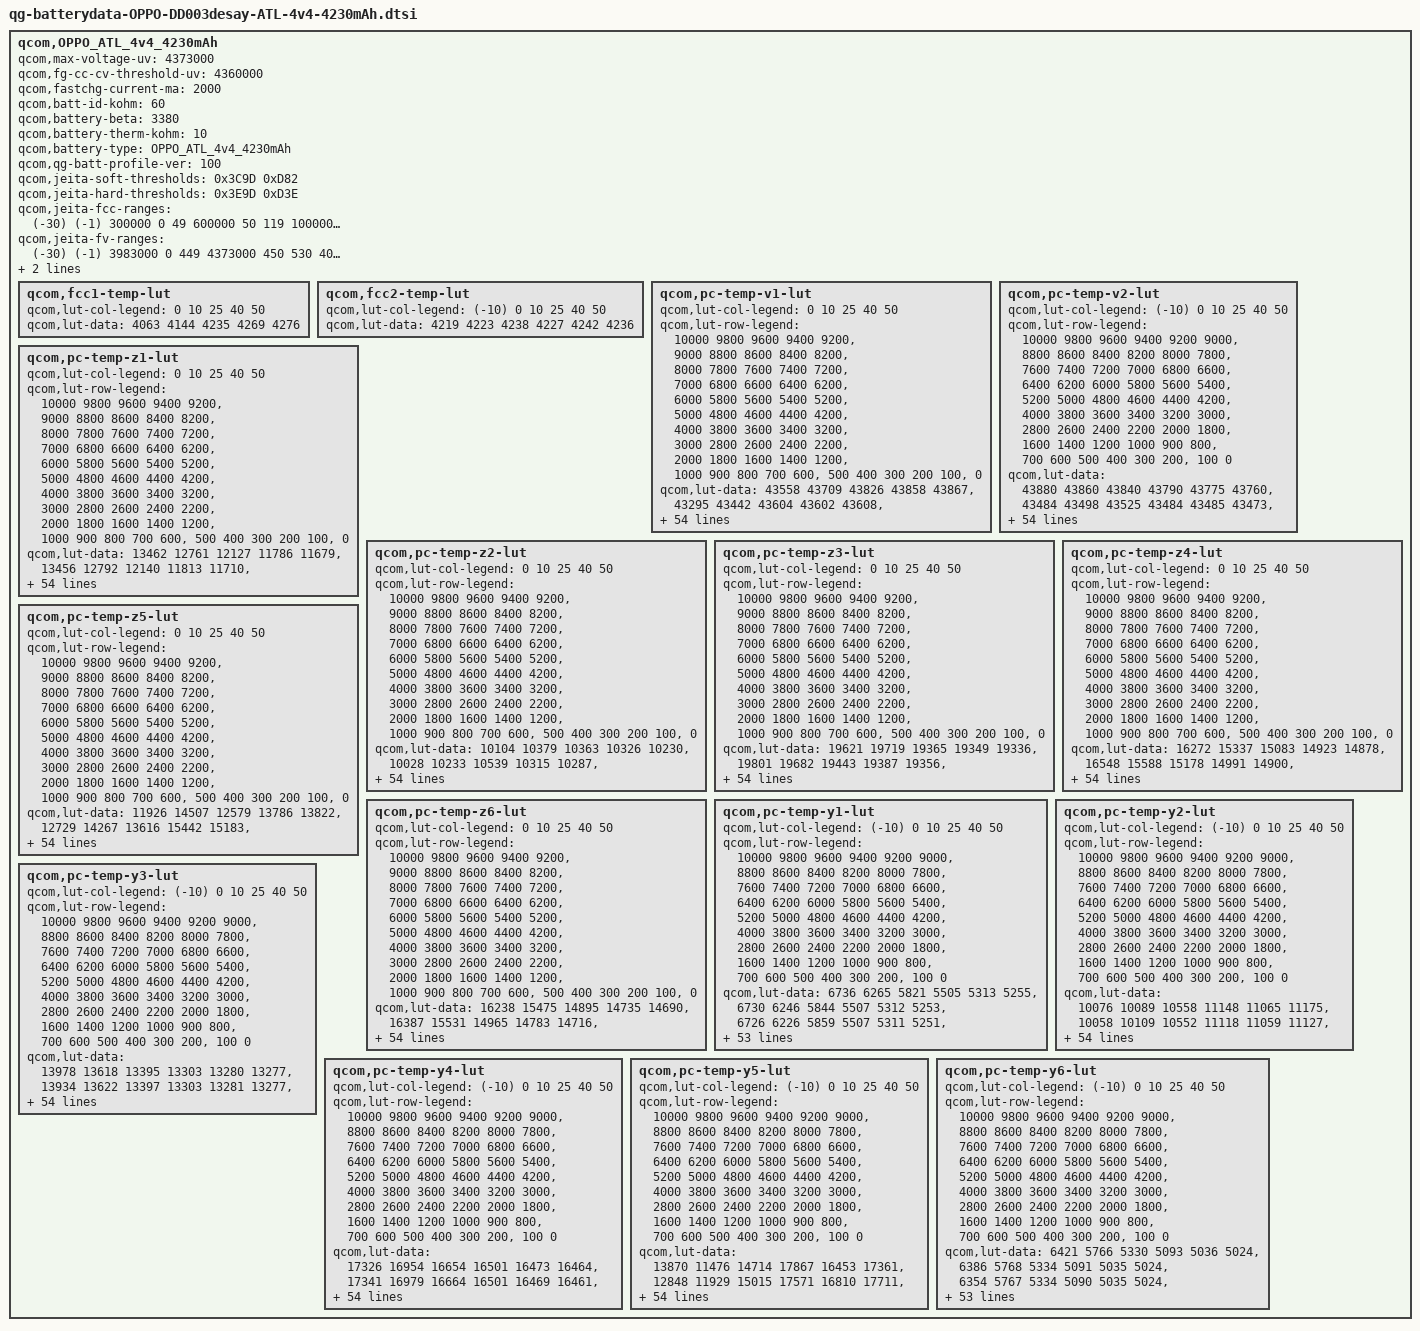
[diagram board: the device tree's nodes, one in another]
/*******************************************************************************
 *  Copyright (C), 2008-2018, OPPO Mobile Comm Corp., Ltd.
 *  ODM_WT_EDIT
 *  FILE: - qg-batterydata-OPPO-DD003desay-ATL-4v4-4230mAh.dtsi
 *  Description : The battery profile of ATL coil
 *  Version: 1.0
 *  Date : 2018/5/16
 *  Author: Bin2.Zhang@ODM_WT.BSP.Charger.Basic
 *
 *  -------------------------Revision History:----------------------------------
 *   <author>	 <data> 	<version >			<desc>
 *  Bin2.Zhang	2018/5/16	1.0				Add battery profile
 ******************************************************************************/
/* Copyright (c) 2018, The Linux Foundation. All rights reserved.
 *
 * This program is free software; you can redistribute it and/or modify
 * it under the terms of the GNU General Public License version 2 and
 * only version 2 as published by the Free Software Foundation.
 *
 * This program is distributed in the hope that it will be useful,
 * but WITHOUT ANY WARRANTY; without even the implied warranty of
 * MERCHANTABILITY or FITNESS FOR A PARTICULAR PURPOSE.  See the
 * GNU General Public License for more details.
 */

qcom,OPPO_ATL_4v4_4230mAh {
    /* 3444982_OPPO_DD003desay_4230mAh_averaged_MasterSlave_May8th2018 */
    qcom,max-voltage-uv = <4373000>;
    qcom,fg-cc-cv-threshold-uv = <4360000>;
    qcom,fastchg-current-ma = <2000>;
    qcom,batt-id-kohm = <60>; // (68|300) + 5.1
    qcom,battery-beta = <3380>;
    qcom,battery-therm-kohm = <10>;
    qcom,battery-type = "OPPO_ATL_4v4_4230mAh";
    qcom,qg-batt-profile-ver = <100>;

    ////From the attached of 80-p3255-39_a
	qcom,jeita-soft-thresholds = <0x3C9D 0xD82>; //disable in kernel
	qcom,jeita-hard-thresholds = <0x3E9D 0xD3E>; //<(-8) 58>;Use SW disable,also Enable in kernel
	qcom,jeita-fcc-ranges = < (-30) (-1) 300000
				0    49  600000
				50   119  1000000
				120  219  1800000
				220  449  2000000
				450  530  1000000>;
	qcom,jeita-fv-ranges = < (-30) (-1) 3983000
				0   449  4373000
				450 530  4083000>;
	qcom,jeita-rechr-uv-ranges = < (-30) (-1) 3700000
				0   49   4150000
				50  449  4270000
				450 530  3980000>;

	qcom,fcc1-temp-lut {
		qcom,lut-col-legend = <0 10 25 40 50>;
		qcom,lut-data = <4063 4144 4235 4269 4276>;
	};

	qcom,fcc2-temp-lut {
		qcom,lut-col-legend = <(-10) 0 10 25 40 50>;
		qcom,lut-data = <4219 4223 4238 4227 4242 4236>;
		//qcom,lut-col-legend = <(-20) (-10) 0 10 25 40 50>;
		//qcom,lut-data = <4218 4219 4223 4238 4227 4242 4236>;
	};

	qcom,pc-temp-v1-lut {
		qcom,lut-col-legend = <0 10 25 40 50>;
		qcom,lut-row-legend = <10000 9800 9600 9400 9200>,
			<9000 8800 8600 8400 8200>,
			<8000 7800 7600 7400 7200>,
			<7000 6800 6600 6400 6200>,
			<6000 5800 5600 5400 5200>,
			<5000 4800 4600 4400 4200>,
			<4000 3800 3600 3400 3200>,
			<3000 2800 2600 2400 2200>,
			<2000 1800 1600 1400 1200>,
			<1000 900 800 700 600>,
			<500 400 300 200 100>,
			<0>;
		qcom,lut-data = <43558 43709 43826 43858 43867>,
			<43295 43442 43604 43602 43608>,
			<43044 43189 43351 43362 43368>,
			<42801 42949 43104 43127 43133>,
			<42566 42715 42858 42891 42902>,
			<42337 42480 42616 42656 42674>,
			<42113 42248 42383 42423 42444>,
			<41894 42022 42155 42192 42213>,
			<41681 41801 41928 41965 41985>,
			<41477 41586 41700 41739 41757>,
			<41282 41378 41478 41516 41531>,
			<41085 41177 41271 41297 41313>,
			<40878 40976 41071 41081 41098>,
			<40666 40780 40868 40873 40890>,
			<40449 40581 40656 40671 40685>,
			<40218 40372 40450 40475 40488>,
			<40009 40156 40251 40284 40299>,
			<39849 39971 40062 40101 40120>,
			<39714 39828 39896 39928 39947>,
			<39584 39699 39760 39778 39791>,
			<39456 39558 39612 39622 39630>,
			<39332 39412 39413 39410 39426>,
			<39209 39249 39185 39146 39178>,
			<39090 39025 38982 38943 38976>,
			<38967 38791 38784 38803 38830>,
			<38831 38644 38635 38689 38708>,
			<38694 38542 38551 38588 38600>,
			<38580 38466 38489 38498 38504>,
			<38479 38413 38424 38413 38414>,
			<38397 38371 38357 38330 38325>,
			<38341 38329 38294 38253 38243>,
			<38296 38287 38234 38185 38171>,
			<38259 38246 38178 38124 38107>,
			<38227 38208 38128 38068 38047>,
			<38198 38172 38086 38018 37993>,
			<38168 38136 38045 37970 37939>,
			<38138 38105 38006 37922 37880>,
			<38102 38067 37965 37874 37819>,
			<38048 38007 37906 37810 37746>,
			<37977 37917 37818 37723 37658>,
			<37889 37817 37716 37621 37558>,
			<37768 37703 37607 37512 37449>,
			<37630 37572 37482 37386 37323>,
			<37473 37412 37322 37229 37166>,
			<37328 37267 37175 37087 37027>,
			<37245 37168 37076 36993 36936>,
			<37216 37143 37052 36965 36913>,
			<37187 37120 37032 36951 36894>,
			<37161 37097 37012 36931 36874>,
			<37114 37059 36968 36876 36814>,
			<36905 36836 36740 36617 36546>,
			<36460 36400 36308 36178 36113>,
			<35885 35827 35737 35602 35544>,
			<35103 35044 34957 34816 34769>,
			<33866 33815 33746 33588 33573>,
			<30000 30000 30000 30000 30000>;
	};

	qcom,pc-temp-v2-lut {
		qcom,lut-col-legend = <(-10) 0 10 25 40 50>;
		qcom,lut-row-legend = <10000 9800 9600 9400 9200 9000>,
			<8800 8600 8400 8200 8000 7800>,
			<7600 7400 7200 7000 6800 6600>,
			<6400 6200 6000 5800 5600 5400>,
			<5200 5000 4800 4600 4400 4200>,
			<4000 3800 3600 3400 3200 3000>,
			<2800 2600 2400 2200 2000 1800>,
			<1600 1400 1200 1000 900 800>,
			<700 600 500 400 300 200>,
			<100 0>;
		qcom,lut-data = <43880 43860 43840 43790 43775 43760>,
			<43484 43498 43525 43484 43485 43473>,
			<43129 43170 43232 43199 43213 43204>,
			<42819 42880 42963 42938 42958 42951>,
			<42544 42626 42718 42700 42721 42716>,
			<42302 42382 42480 42467 42489 42486>,
			<42100 42141 42241 42233 42257 42253>,
			<41915 41905 42007 42003 42026 42023>,
			<41685 41674 41779 41777 41798 41797>,
			<41394 41443 41558 41556 41573 41572>,
			<41158 41232 41343 41339 41352 41351>,
			<41040 41061 41137 41125 41136 41135>,
			<40943 40901 40936 40914 40924 40921>,
			<40734 40700 40736 40709 40720 40717>,
			<40270 40452 40535 40507 40520 40517>,
			<39852 40191 40331 40311 40327 40325>,
			<39624 39920 40119 40114 40137 40140>,
			<39446 39652 39904 39925 39953 39962>,
			<39273 39441 39688 39757 39783 39793>,
			<39112 39273 39469 39614 39629 39637>,
			<38956 39116 39264 39454 39458 39465>,
			<38795 38961 39073 39224 39234 39243>,
			<38640 38812 38897 38971 38999 39010>,
			<38509 38656 38742 38785 38817 38827>,
			<38395 38488 38602 38640 38664 38675>,
			<38297 38344 38479 38516 38534 38545>,
			<38216 38236 38373 38406 38423 38432>,
			<38146 38146 38276 38307 38325 38333>,
			<38081 38077 38176 38217 38235 38242>,
			<38019 38021 38074 38133 38153 38158>,
			<37961 37971 37991 38058 38079 38082>,
			<37904 37923 37928 37989 38011 38013>,
			<37850 37877 37877 37925 37948 37949>,
			<37792 37831 37831 37865 37882 37881>,
			<37733 37787 37792 37811 37814 37812>,
			<37673 37741 37753 37755 37740 37733>,
			<37612 37693 37715 37695 37651 37626>,
			<37549 37640 37675 37633 37559 37510>,
			<37482 37580 37621 37564 37476 37416>,
			<37409 37514 37550 37492 37398 37337>,
			<37338 37437 37467 37411 37315 37255>,
			<37270 37343 37367 37314 37224 37163>,
			<37205 37233 37249 37201 37119 37059>,
			<37141 37109 37106 37068 36983 36928>,
			<37070 36993 36972 36940 36866 36816>,
			<36978 36898 36877 36871 36819 36769>,
			<36922 36856 36846 36859 36805 36755>,
			<36865 36818 36813 36839 36790 36741>,
			<36790 36775 36770 36810 36761 36711>,
			<36675 36700 36679 36739 36665 36616>,
			<36449 36512 36471 36482 36353 36300>,
			<36054 36095 36032 36006 35845 35811>,
			<35458 35479 35408 35391 35193 35171>,
			<34592 34622 34540 34532 34292 34298>,
			<33160 33237 33217 33208 32875 32956>,
			<28418 27954 28007 28289 27814 28701>;
	};

	qcom,pc-temp-z1-lut {
		qcom,lut-col-legend = <0 10 25 40 50>;
		qcom,lut-row-legend = <10000 9800 9600 9400 9200>,
			<9000 8800 8600 8400 8200>,
			<8000 7800 7600 7400 7200>,
			<7000 6800 6600 6400 6200>,
			<6000 5800 5600 5400 5200>,
			<5000 4800 4600 4400 4200>,
			<4000 3800 3600 3400 3200>,
			<3000 2800 2600 2400 2200>,
			<2000 1800 1600 1400 1200>,
			<1000 900 800 700 600>,
			<500 400 300 200 100>,
			<0>;
		qcom,lut-data = <13462 12761 12127 11786 11679>,
			<13456 12792 12140 11813 11710>,
			<13463 12797 12137 11814 11711>,
			<13469 12779 12133 11813 11712>,
			<13462 12764 12124 11809 11712>,
			<13444 12757 12115 11803 11712>,
			<13434 12743 12105 11800 11712>,
			<13433 12735 12096 11797 11713>,
			<13435 12717 12089 11796 11713>,
			<13437 12698 12082 11796 11714>,
			<13440 12690 12079 11796 11715>,
			<13440 12684 12079 11796 11715>,
			<13411 12676 12080 11796 11716>,
			<13366 12664 12080 11796 11716>,
			<13350 12651 12076 11794 11716>,
			<13346 12642 12074 11792 11715>,
			<13342 12630 12075 11792 11716>,
			<13327 12626 12077 11793 11716>,
			<13296 12630 12078 11794 11717>,
			<13284 12637 12080 11796 11719>,
			<13289 12641 12082 11798 11720>,
			<13294 12647 12086 11799 11721>,
			<13298 12651 12092 11801 11722>,
			<13300 12655 12096 11802 11723>,
			<13303 12659 12099 11805 11725>,
			<13311 12663 12102 11808 11727>,
			<13320 12673 12105 11811 11730>,
			<13323 12678 12109 11815 11733>,
			<13316 12677 12113 11819 11737>,
			<13311 12676 12117 11823 11741>,
			<13319 12677 12122 11828 11745>,
			<13332 12678 12128 11832 11749>,
			<13337 12681 12136 11837 11753>,
			<13339 12688 12144 11842 11756>,
			<13343 12700 12151 11845 11760>,
			<13349 12707 12157 11849 11763>,
			<13361 12719 12161 11853 11766>,
			<13371 12729 12165 11859 11768>,
			<13382 12733 12168 11863 11771>,
			<13394 12743 12175 11867 11774>,
			<13397 12751 12182 11871 11776>,
			<13396 12759 12192 11876 11780>,
			<13396 12766 12201 11880 11783>,
			<13397 12761 12201 11883 11786>,
			<13397 12775 12211 11888 11790>,
			<13412 12780 12215 11892 11791>,
			<13409 12773 12225 11893 11792>,
			<13426 12780 12215 11893 11793>,
			<13414 12753 12214 11895 11794>,
			<13397 12760 12224 11899 11798>,
			<13409 12802 12223 11906 11803>,
			<13452 12800 12245 11913 11809>,
			<13482 12806 12255 11921 11818>,
			<13458 12841 12268 11936 11830>,
			<13458 12841 12268 11936 11830>,
			<13458 12841 12268 11936 11830>;
	};

	qcom,pc-temp-z2-lut {
		qcom,lut-col-legend = <0 10 25 40 50>;
		qcom,lut-row-legend = <10000 9800 9600 9400 9200>,
			<9000 8800 8600 8400 8200>,
			<8000 7800 7600 7400 7200>,
			<7000 6800 6600 6400 6200>,
			<6000 5800 5600 5400 5200>,
			<5000 4800 4600 4400 4200>,
			<4000 3800 3600 3400 3200>,
			<3000 2800 2600 2400 2200>,
			<2000 1800 1600 1400 1200>,
			<1000 900 800 700 600>,
			<500 400 300 200 100>,
			<0>;
		qcom,lut-data = <10104 10379 10363 10326 10230>,
			<10028 10233 10539 10315 10287>,
			<10048 10183 10931 10462 10468>,
			<10071 10170 10999 10558 10596>,
			<10089 10159 10639 10543 10572>,
			<10108 10137 10344 10513 10522>,
			<10118 10111 10404 10483 10488>,
			<10124 10096 10542 10442 10453>,
			<10127 10086 10554 10417 10433>,
			<10126 10080 10386 10609 10439>,
			<10115 10079 10255 10899 10451>,
			<10101 10079 10300 10944 10426>,
			<10075 10081 10409 10923 10307>,
			<10040 10099 10502 10910 10239>,
			<10012 10125 10596 10929 10272>,
			<9983 10144 10652 10956 10316>,
			<9966 10159 10572 10872 10325>,
			<9971 10180 10415 10525 10326>,
			<9990 10223 10382 10346 10329>,
			<10008 10263 10399 10332 10345>,
			<10026 10272 10423 10328 10376>,
			<10042 10274 10463 10429 10472>,
			<10054 10276 10509 10668 10690>,
			<10061 10277 10513 10752 10778>,
			<10070 10278 10470 10543 10604>,
			<10082 10280 10435 10328 10413>,
			<10097 10283 10432 10330 10419>,
			<10110 10287 10434 10381 10487>,
			<10124 10291 10445 10444 10529>,
			<10138 10296 10484 10546 10550>,
			<10149 10301 10510 10622 10560>,
			<10159 10308 10503 10588 10488>,
			<10171 10317 10488 10500 10321>,
			<10185 10326 10479 10473 10265>,
			<10200 10335 10470 10504 10300>,
			<10216 10342 10465 10544 10351>,
			<10235 10346 10480 10571 10402>,
			<10252 10350 10511 10596 10458>,
			<10265 10359 10537 10628 10502>,
			<10279 10374 10562 10677 10541>,
			<10295 10385 10582 10707 10565>,
			<10317 10391 10594 10689 10561>,
			<10345 10400 10604 10654 10549>,
			<10385 10429 10614 10633 10534>,
			<10701 10620 10686 10624 10528>,
			<10558 10709 10738 10602 10536>,
			<10463 10733 10730 10580 10539>,
			<10427 10752 10708 10607 10529>,
			<10418 10781 10712 10615 10564>,
			<10397 10900 10752 10762 10695>,
			<10386 10850 10933 10747 10482>,
			<10305 10804 10847 10570 10343>,
			<10079 10697 10816 10494 10283>,
			<9915 10548 10747 10438 10230>,
			<9915 10548 10747 10438 10230>,
			<9915 10548 10747 10438 10230>;
	};

	qcom,pc-temp-z3-lut {
		qcom,lut-col-legend = <0 10 25 40 50>;
		qcom,lut-row-legend = <10000 9800 9600 9400 9200>,
			<9000 8800 8600 8400 8200>,
			<8000 7800 7600 7400 7200>,
			<7000 6800 6600 6400 6200>,
			<6000 5800 5600 5400 5200>,
			<5000 4800 4600 4400 4200>,
			<4000 3800 3600 3400 3200>,
			<3000 2800 2600 2400 2200>,
			<2000 1800 1600 1400 1200>,
			<1000 900 800 700 600>,
			<500 400 300 200 100>,
			<0>;
		qcom,lut-data = <19621 19719 19365 19349 19336>,
			<19801 19682 19443 19387 19356>,
			<19885 19684 19478 19410 19383>,
			<19923 19702 19498 19424 19399>,
			<19917 19713 19514 19433 19402>,
			<19896 19715 19526 19438 19404>,
			<19874 19715 19534 19438 19405>,
			<19845 19714 19540 19434 19404>,
			<19822 19705 19537 19431 19403>,
			<19819 19693 19519 19432 19400>,
			<19820 19686 19504 19436 19395>,
			<19821 19679 19507 19435 19388>,
			<19829 19669 19518 19428 19376>,
			<19841 19644 19518 19422 19369>,
			<19852 19620 19507 19416 19366>,
			<19874 19613 19492 19410 19364>,
			<19891 19610 19475 19402 19361>,
			<19879 19605 19458 19384 19355>,
			<19846 19583 19450 19372 19350>,
			<19822 19559 19442 19366 19346>,
			<19807 19560 19438 19362 19343>,
			<19797 19579 19450 19369 19347>,
			<19796 19600 19471 19389 19361>,
			<19797 19620 19475 19397 19366>,
			<19799 19637 19469 19377 19348>,
			<19811 19639 19459 19356 19327>,
			<19828 19636 19448 19353 19326>,
			<19831 19630 19437 19352 19332>,
			<19827 19621 19435 19354 19341>,
			<19819 19610 19441 19377 19365>,
			<19809 19602 19448 19400 19386>,
			<19795 19597 19459 19402 19385>,
			<19780 19594 19470 19403 19379>,
			<19764 19593 19472 19403 19372>,
			<19747 19593 19466 19396 19364>,
			<19732 19592 19460 19388 19358>,
			<19716 19586 19454 19383 19356>,
			<19705 19580 19449 19378 19355>,
			<19700 19578 19446 19374 19354>,
			<19696 19577 19443 19371 19351>,
			<19689 19575 19440 19368 19349>,
			<19677 19569 19435 19367 19350>,
			<19663 19559 19429 19365 19351>,
			<19645 19544 19425 19363 19352>,
			<19555 19495 19411 19355 19348>,
			<19403 19475 19402 19350 19342>,
			<19338 19452 19393 19350 19330>,
			<19336 19442 19388 19338 19329>,
			<19327 19434 19388 19336 19325>,
			<19316 19386 19384 19327 19320>,
			<19328 19429 19357 19326 19345>,
			<19334 19382 19354 19342 19348>,
			<19341 19345 19349 19344 19349>,
			<19344 19344 19343 19345 19350>,
			<19344 19344 19343 19345 19350>,
			<19344 19344 19343 19345 19350>;
	};

	qcom,pc-temp-z4-lut {
		qcom,lut-col-legend = <0 10 25 40 50>;
		qcom,lut-row-legend = <10000 9800 9600 9400 9200>,
			<9000 8800 8600 8400 8200>,
			<8000 7800 7600 7400 7200>,
			<7000 6800 6600 6400 6200>,
			<6000 5800 5600 5400 5200>,
			<5000 4800 4600 4400 4200>,
			<4000 3800 3600 3400 3200>,
			<3000 2800 2600 2400 2200>,
			<2000 1800 1600 1400 1200>,
			<1000 900 800 700 600>,
			<500 400 300 200 100>,
			<0>;
		qcom,lut-data = <16272 15337 15083 14923 14878>,
			<16548 15588 15178 14991 14900>,
			<16306 15590 15119 14959 14888>,
			<16021 15421 15064 14921 14870>,
			<15844 15249 15005 14887 14848>,
			<15696 15149 14947 14854 14823>,
			<15579 15070 14888 14829 14802>,
			<15492 15009 14831 14809 14783>,
			<15417 14961 14806 14788 14766>,
			<15342 14921 14795 14757 14750>,
			<15271 14889 14787 14724 14737>,
			<15205 14861 14755 14711 14733>,
			<15144 14840 14705 14704 14731>,
			<15088 14825 14689 14698 14729>,
			<15040 14813 14693 14690 14720>,
			<14995 14807 14700 14682 14709>,
			<14958 14802 14707 14681 14701>,
			<14933 14798 14714 14690 14694>,
			<14914 14794 14711 14694 14689>,
			<14894 14789 14698 14689 14683>,
			<14870 14777 14690 14684 14679>,
			<14847 14750 14704 14700 14692>,
			<14830 14736 14738 14756 14744>,
			<14816 14778 14777 14801 14789>,
			<14807 14842 14835 14832 14822>,
			<14806 14858 14870 14852 14844>,
			<14807 14861 14864 14849 14839>,
			<14811 14862 14850 14835 14818>,
			<14822 14854 14834 14814 14791>,
			<14831 14835 14811 14775 14748>,
			<14829 14819 14786 14735 14710>,
			<14822 14804 14758 14715 14698>,
			<14815 14790 14732 14700 14690>,
			<14809 14775 14720 14694 14687>,
			<14804 14759 14713 14691 14685>,
			<14799 14749 14710 14690 14685>,
			<14795 14742 14709 14692 14686>,
			<14790 14738 14709 14696 14692>,
			<14780 14739 14711 14702 14698>,
			<14770 14742 14724 14715 14709>,
			<14768 14743 14734 14723 14715>,
			<14772 14741 14729 14718 14709>,
			<14772 14739 14723 14711 14700>,
			<14762 14738 14722 14714 14701>,
			<14750 14722 14710 14709 14695>,
			<14878 14707 14690 14690 14680>,
			<14945 14721 14687 14681 14680>,
			<14943 14724 14677 14674 14665>,
			<14944 14723 14663 14657 14646>,
			<14945 14770 14666 14664 14648>,
			<14934 14732 14717 14699 14658>,
			<14953 14802 14731 14689 14662>,
			<14960 14848 14739 14691 14663>,
			<14974 14858 14751 14691 14664>,
			<14974 14858 14751 14691 14664>,
			<14974 14858 14751 14691 14664>;
	};

	qcom,pc-temp-z5-lut {
		qcom,lut-col-legend = <0 10 25 40 50>;
		qcom,lut-row-legend = <10000 9800 9600 9400 9200>,
			<9000 8800 8600 8400 8200>,
			<8000 7800 7600 7400 7200>,
			<7000 6800 6600 6400 6200>,
			<6000 5800 5600 5400 5200>,
			<5000 4800 4600 4400 4200>,
			<4000 3800 3600 3400 3200>,
			<3000 2800 2600 2400 2200>,
			<2000 1800 1600 1400 1200>,
			<1000 900 800 700 600>,
			<500 400 300 200 100>,
			<0>;
		qcom,lut-data = <11926 14507 12579 13786 13822>,
			<12729 14267 13616 15442 15183>,
			<13292 14495 14694 16564 17074>,
			<13624 14948 15517 17369 18186>,
			<13714 15429 16427 17992 18368>,
			<13766 15902 17380 18456 18467>,
			<13789 16368 18463 18650 18627>,
			<13757 16739 19552 18702 18854>,
			<13720 17007 19870 18696 19141>,
			<13776 17294 19584 20868 19653>,
			<13993 17821 19386 24109 20188>,
			<14234 18502 22212 24737 20067>,
			<14477 18732 27514 24904 19123>,
			<14803 18606 28961 24948 18590>,
			<15335 18469 28413 26043 19197>,
			<16711 18663 27470 27560 20075>,
			<17787 19285 25488 26803 20367>,
			<17745 19562 22910 22845 20496>,
			<17522 18870 22492 20972 20664>,
			<17450 18017 23238 21457 21151>,
			<18094 18845 24579 22370 22045>,
			<19260 23576 34044 27157 24875>,
			<20558 29731 49205 38487 31150>,
			<22306 39430 51496 42527 33563>,
			<24807 49227 42374 32165 26101>,
			<30979 50149 32823 20598 17532>,
			<38782 44788 26952 17939 16095>,
			<41605 38823 22436 16617 15603>,
			<41954 34173 21395 16411 15631>,
			<41440 30076 21272 18342 18444>,
			<39695 28263 21312 21260 21987>,
			<36548 27349 23854 24268 23694>,
			<33602 26923 28525 27670 24897>,
			<30869 27727 31000 29980 25978>,
			<28430 29556 32679 31738 27125>,
			<26665 30298 33483 32689 27878>,
			<25051 30265 33396 32098 28059>,
			<24308 30229 33139 30362 28161>,
			<24956 30889 32517 28358 27883>,
			<26027 32415 30436 25587 24904>,
			<26236 32987 28106 23208 22154>,
			<25707 30994 25997 22018 21595>,
			<25343 28577 24372 21139 21327>,
			<25648 26533 23623 20247 21222>,
			<23842 26146 23878 19683 20693>,
			<15775 25923 24828 19787 20146>,
			<12452 20500 22421 20304 17790>,
			<12394 19270 22093 18536 18491>,
			<12255 18856 23353 19782 20644>,
			<12122 16513 22675 17896 19170>,
			<12411 18443 16129 15004 19686>,
			<12318 14548 14985 15775 18696>,
			<12220 12895 14388 15568 18031>,
			<12068 12653 13788 15296 17340>,
			<12068 12653 13788 15296 17340>,
			<12068 12653 13788 15296 17340>;
	};

	qcom,pc-temp-z6-lut {
		qcom,lut-col-legend = <0 10 25 40 50>;
		qcom,lut-row-legend = <10000 9800 9600 9400 9200>,
			<9000 8800 8600 8400 8200>,
			<8000 7800 7600 7400 7200>,
			<7000 6800 6600 6400 6200>,
			<6000 5800 5600 5400 5200>,
			<5000 4800 4600 4400 4200>,
			<4000 3800 3600 3400 3200>,
			<3000 2800 2600 2400 2200>,
			<2000 1800 1600 1400 1200>,
			<1000 900 800 700 600>,
			<500 400 300 200 100>,
			<0>;
		qcom,lut-data = <16238 15475 14895 14735 14690>,
			<16387 15531 14965 14783 14716>,
			<16278 15527 14960 14782 14724>,
			<16141 15442 14950 14779 14726>,
			<16033 15348 14929 14770 14721>,
			<15930 15292 14904 14756 14710>,
			<15844 15245 14882 14744 14701>,
			<15773 15205 14859 14733 14694>,
			<15713 15170 14841 14723 14686>,
			<15665 15140 14827 14711 14678>,
			<15624 15117 14813 14700 14670>,
			<15587 15098 14798 14692 14663>,
			<15548 15076 14784 14686 14656>,
			<15512 15047 14775 14679 14650>,
			<15488 15022 14771 14672 14645>,
			<15471 15014 14767 14665 14639>,
			<15456 15009 14761 14659 14633>,
			<15432 15004 14754 14653 14627>,
			<15403 14990 14746 14647 14622>,
			<15380 14978 14738 14642 14617>,
			<15360 14976 14733 14638 14613>,
			<15346 14978 14745 14650 14622>,
			<15341 14981 14771 14688 14655>,
			<15338 15009 14793 14705 14672>,
			<15337 15048 14814 14707 14675>,
			<15343 15057 14825 14708 14677>,
			<15354 15058 14819 14706 14675>,
			<15360 15058 14808 14700 14670>,
			<15363 15052 14801 14694 14664>,
			<15365 15039 14795 14690 14660>,
			<15363 15030 14790 14685 14655>,
			<15354 15023 14785 14680 14650>,
			<15344 15017 14781 14675 14644>,
			<15335 15012 14777 14671 14639>,
			<15326 15008 14773 14666 14634>,
			<15319 15004 14770 14663 14631>,
			<15312 15001 14767 14662 14631>,
			<15309 14999 14765 14661 14632>,
			<15309 15001 14766 14661 14634>,
			<15309 15006 14772 14665 14637>,
			<15309 15009 14776 14668 14639>,
			<15311 15009 14773 14666 14637>,
			<15312 15008 14770 14663 14634>,
			<15308 15006 14769 14663 14635>,
			<15267 14986 14760 14658 14631>,
			<15251 14973 14749 14648 14623>,
			<15246 14967 14744 14644 14617>,
			<15245 14963 14737 14635 14609>,
			<15241 14960 14732 14626 14599>,
			<15241 14959 14733 14626 14597>,
			<15251 14972 14743 14642 14616>,
			<15269 14984 14751 14648 14622>,
			<15289 14994 14756 14652 14625>,
			<15319 15012 14763 14656 14630>,
			<15319 15012 14763 14656 14630>,
			<15319 15012 14763 14656 14630>;
	};

	qcom,pc-temp-y1-lut {
		qcom,lut-col-legend = <(-10) 0 10 25 40 50>;
		qcom,lut-row-legend = <10000 9800 9600 9400 9200 9000>,
			<8800 8600 8400 8200 8000 7800>,
			<7600 7400 7200 7000 6800 6600>,
			<6400 6200 6000 5800 5600 5400>,
			<5200 5000 4800 4600 4400 4200>,
			<4000 3800 3600 3400 3200 3000>,
			<2800 2600 2400 2200 2000 1800>,
			<1600 1400 1200 1000 900 800>,
			<700 600 500 400 300 200>,
			<100 0>;
		qcom,lut-data = <6736 6265 5821 5505 5313 5255>,
			<6730 6246 5844 5507 5312 5253>,
			<6726 6226 5859 5507 5311 5251>,
			<6722 6208 5867 5507 5310 5249>,
			<6720 6195 5871 5506 5309 5247>,
			<6720 6190 5872 5505 5307 5245>,
			<6721 6193 5866 5502 5305 5244>,
			<6723 6198 5854 5497 5303 5244>,
			<6722 6201 5848 5495 5301 5243>,
			<6718 6202 5841 5494 5300 5242>,
			<6713 6202 5837 5493 5298 5241>,
			<6716 6206 5838 5492 5297 5240>,
			<6722 6213 5841 5490 5296 5240>,
			<6723 6215 5841 5490 5295 5239>,
			<6717 6215 5839 5488 5294 5239>,
			<6713 6215 5839 5488 5294 5239>,
			<6714 6213 5846 5488 5295 5240>,
			<6716 6210 5855 5488 5296 5241>,
			<6716 6209 5855 5489 5296 5241>,
			<6713 6209 5846 5490 5296 5241>,
			<6710 6209 5842 5492 5296 5241>,
			<6712 6208 5846 5493 5297 5241>,
			<6715 6207 5854 5495 5298 5242>,
			<6712 6208 5856 5497 5299 5242>,
			<6698 6218 5855 5503 5301 5244>,
			<6684 6224 5854 5508 5303 5246>,
			<6674 6223 5851 5511 5305 5247>,
			<6666 6220 5848 5515 5307 5249>,
			<6662 6215 5849 5520 5310 5251>,
			<6658 6209 5851 5529 5313 5254>,
			<6656 6204 5854 5534 5317 5256>,
			<6657 6199 5856 5534 5320 5259>,
			<6659 6192 5858 5534 5324 5261>,
			<6660 6192 5859 5536 5328 5264>,
			<6665 6197 5863 5543 5332 5266>,
			<6669 6201 5866 5549 5335 5269>,
			<6659 6204 5873 5553 5337 5270>,
			<6643 6208 5882 5557 5338 5272>,
			<6634 6205 5884 5558 5340 5273>,
			<6631 6189 5883 5557 5341 5275>,
			<6628 6177 5882 5557 5343 5277>,
			<6628 6187 5871 5561 5344 5278>,
			<6631 6197 5863 5566 5346 5280>,
			<6643 6179 5873 5573 5349 5282>,
			<6657 6184 5891 5586 5354 5285>,
			<6692 6219 5878 5584 5359 5287>,
			<6691 6212 5884 5586 5359 5288>,
			<6667 6200 5875 5586 5360 5287>,
			<6702 6195 5878 5598 5359 5287>,
			<6703 6209 5884 5607 5359 5288>,
			<6693 6198 5899 5603 5362 5290>,
			<6688 6211 5917 5607 5369 5295>,
			<6680 6222 5917 5629 5377 5301>,
			<6735 6237 5918 5639 5388 5310>,
			<6735 6237 5918 5639 5388 5310>,
			<6735 6237 5918 5639 5388 5310>;
	};

	qcom,pc-temp-y2-lut {
		qcom,lut-col-legend = <(-10) 0 10 25 40 50>;
		qcom,lut-row-legend = <10000 9800 9600 9400 9200 9000>,
			<8800 8600 8400 8200 8000 7800>,
			<7600 7400 7200 7000 6800 6600>,
			<6400 6200 6000 5800 5600 5400>,
			<5200 5000 4800 4600 4400 4200>,
			<4000 3800 3600 3400 3200 3000>,
			<2800 2600 2400 2200 2000 1800>,
			<1600 1400 1200 1000 900 800>,
			<700 600 500 400 300 200>,
			<100 0>;
		qcom,lut-data = <10076 10089 10558 11148 11065 11175>,
			<10058 10109 10552 11118 11059 11127>,
			<10062 10134 10549 11080 11038 11080>,
			<10086 10159 10548 11042 11009 11035>,
			<10123 10180 10548 11009 10982 10995>,
			<10171 10193 10550 10990 10964 10962>,
			<10237 10197 10552 10983 10947 10934>,
			<10316 10201 10556 10978 10930 10910>,
			<10387 10235 10562 10969 10932 10894>,
			<10462 10379 10572 10951 10958 10881>,
			<10510 10476 10586 10941 10988 10876>,
			<10529 10475 10607 10947 11021 10895>,
			<10543 10471 10640 10962 11052 10931>,
			<10514 10486 10691 10983 11063 10960>,
			<10342 10560 10784 11021 11074 10989>,
			<10222 10645 10847 11062 11089 11010>,
			<10046 10711 10864 11101 11130 11046>,
			<9757 10776 10875 11141 11196 11108>,
			<9685 10850 10892 11186 11263 11185>,
			<9680 10946 10912 11240 11344 11303>,
			<9678 10998 10937 11268 11381 11363>,
			<9676 10956 10967 11247 11323 11274>,
			<9675 10882 11003 11213 11236 11147>,
			<9673 10848 11042 11209 11202 11130>,
			<9672 10837 11088 11226 11183 11146>,
			<9670 10819 11120 11249 11176 11162>,
			<9669 10462 11136 11288 11195 11177>,
			<9668 9886 11145 11334 11232 11199>,
			<9668 9729 11145 11361 11277 11250>,
			<9667 9702 11136 11376 11350 11365>,
			<9666 9689 11127 11391 11414 11457>,
			<9665 9684 11122 11412 11469 11509>,
			<9665 9682 11115 11432 11510 11543>,
			<9664 9679 11103 11435 11513 11544>,
			<9664 9676 11080 11429 11509 11521>,
			<9663 9673 11055 11419 11502 11485>,
			<9663 9671 11035 11398 11487 11399>,
			<9663 9669 11014 11366 11465 11303>,
			<9662 9667 10982 11345 11432 11277>,
			<9662 9665 10935 11330 11379 11272>,
			<9661 9664 10882 11314 11353 11263>,
			<9661 9663 10827 11290 11367 11218>,
			<9661 9662 10743 11256 11374 11190>,
			<9661 9661 10361 11208 11326 11211>,
			<9660 9660 10013 11129 11191 11130>,
			<9660 9660 9939 11143 11154 11005>,
			<9660 9659 9839 11123 11150 10966>,
			<9659 9659 9762 11104 11158 11063>,
			<9659 9658 9723 11090 11159 11054>,
			<9658 9658 9705 11096 11174 11067>,
			<9658 9657 9694 11036 11105 10953>,
			<9657 9657 9680 10968 11040 10887>,
			<9656 9656 9669 10884 10995 10807>,
			<9653 9655 9662 10816 10917 10755>,
			<9653 9655 9662 10816 10917 10755>,
			<9653 9655 9662 10816 10917 10755>;
	};

	qcom,pc-temp-y3-lut {
		qcom,lut-col-legend = <(-10) 0 10 25 40 50>;
		qcom,lut-row-legend = <10000 9800 9600 9400 9200 9000>,
			<8800 8600 8400 8200 8000 7800>,
			<7600 7400 7200 7000 6800 6600>,
			<6400 6200 6000 5800 5600 5400>,
			<5200 5000 4800 4600 4400 4200>,
			<4000 3800 3600 3400 3200 3000>,
			<2800 2600 2400 2200 2000 1800>,
			<1600 1400 1200 1000 900 800>,
			<700 600 500 400 300 200>,
			<100 0>;
		qcom,lut-data = <13978 13618 13395 13303 13280 13277>,
			<13934 13622 13397 13303 13281 13277>,
			<13883 13624 13398 13303 13282 13278>,
			<13835 13623 13400 13303 13283 13279>,
			<13799 13622 13401 13304 13284 13279>,
			<13785 13619 13401 13304 13285 13280>,
			<13793 13611 13401 13304 13286 13281>,
			<13806 13602 13401 13305 13287 13283>,
			<13784 13599 13400 13306 13288 13284>,
			<13646 13601 13400 13310 13288 13285>,
			<13552 13601 13399 13314 13289 13285>,
			<13555 13553 13399 13314 13292 13286>,
			<13560 13479 13399 13314 13296 13287>,
			<13558 13468 13397 13315 13297 13287>,
			<13538 13491 13388 13315 13297 13289>,
			<13518 13506 13382 13316 13297 13290>,
			<13501 13487 13384 13314 13298 13290>,
			<13487 13450 13387 13312 13298 13291>,
			<13485 13426 13386 13313 13298 13291>,
			<13488 13408 13374 13316 13296 13292>,
			<13490 13395 13363 13319 13293 13292>,
			<13490 13386 13356 13315 13291 13288>,
			<13489 13379 13351 13308 13288 13282>,
			<13486 13376 13345 13304 13286 13280>,
			<13477 13374 13340 13301 13283 13279>,
			<13470 13373 13337 13300 13282 13279>,
			<13476 13372 13335 13299 13281 13278>,
			<13490 13369 13334 13298 13281 13278>,
			<13507 13367 13332 13298 13281 13278>,
			<13530 13362 13330 13298 13281 13279>,
			<13555 13359 13329 13298 13282 13279>,
			<13577 13369 13328 13299 13283 13279>,
			<13597 13386 13327 13299 13285 13279>,
			<13618 13401 13328 13299 13285 13280>,
			<13637 13415 13330 13300 13284 13280>,
			<13658 13431 13332 13300 13284 13280>,
			<13685 13450 13335 13300 13284 13279>,
			<13715 13474 13339 13300 13283 13278>,
			<13744 13499 13340 13300 13283 13277>,
			<13771 13530 13341 13300 13283 13278>,
			<13800 13564 13342 13300 13283 13279>,
			<13833 13599 13344 13300 13284 13280>,
			<13872 13638 13345 13300 13284 13280>,
			<13920 13682 13346 13301 13282 13279>,
			<13968 13729 13351 13302 13282 13280>,
			<13925 13716 13350 13300 13286 13284>,
			<13948 13748 13360 13306 13288 13286>,
			<14004 13799 13378 13308 13295 13291>,
			<14063 13860 13401 13314 13299 13293>,
			<14136 13916 13419 13319 13299 13292>,
			<14222 13972 13435 13315 13292 13287>,
			<14347 14047 13453 13314 13291 13288>,
			<14534 14180 13519 13325 13297 13290>,
			<15105 14362 13643 13334 13303 13297>,
			<15105 14362 13643 13334 13303 13297>,
			<15105 14362 13643 13334 13303 13297>;
	};

	qcom,pc-temp-y4-lut {
		qcom,lut-col-legend = <(-10) 0 10 25 40 50>;
		qcom,lut-row-legend = <10000 9800 9600 9400 9200 9000>,
			<8800 8600 8400 8200 8000 7800>,
			<7600 7400 7200 7000 6800 6600>,
			<6400 6200 6000 5800 5600 5400>,
			<5200 5000 4800 4600 4400 4200>,
			<4000 3800 3600 3400 3200 3000>,
			<2800 2600 2400 2200 2000 1800>,
			<1600 1400 1200 1000 900 800>,
			<700 600 500 400 300 200>,
			<100 0>;
		qcom,lut-data = <17326 16954 16654 16501 16473 16464>,
			<17341 16979 16664 16501 16469 16461>,
			<17349 17000 16675 16501 16466 16459>,
			<17349 17017 16686 16503 16465 16457>,
			<17343 17028 16695 16504 16465 16457>,
			<17332 17032 16698 16506 16465 16456>,
			<17254 17029 16697 16510 16466 16457>,
			<17140 17021 16694 16514 16468 16458>,
			<17147 17006 16694 16517 16471 16460>,
			<17315 16962 16699 16519 16476 16463>,
			<17434 16935 16707 16521 16481 16466>,
			<17443 17056 16719 16527 16483 16471>,
			<17446 17249 16738 16537 16485 16476>,
			<17402 17264 16767 16550 16489 16481>,
			<17152 17115 16815 16570 16500 16486>,
			<16974 16977 16841 16590 16512 16492>,
			<16983 16910 16814 16608 16522 16499>,
			<17008 16861 16764 16624 16534 16509>,
			<17002 16840 16723 16636 16553 16523>,
			<16960 16830 16684 16646 16584 16545>,
			<16910 16819 16651 16651 16599 16557>,
			<16855 16795 16624 16603 16563 16537>,
			<16804 16761 16603 16525 16509 16502>,
			<16794 16713 16593 16498 16485 16481>,
			<16798 16637 16587 16489 16470 16466>,
			<16800 16592 16582 16485 16464 16459>,
			<16800 16607 16578 16488 16468 16461>,
			<16798 16637 16573 16494 16474 16466>,
			<16795 16658 16563 16500 16481 16471>,
			<16788 16677 16541 16506 16490 16479>,
			<16783 16688 16529 16513 16499 16488>,
			<16782 16690 16533 16520 16511 16501>,
			<16781 16689 16540 16526 16521 16512>,
			<16781 16692 16548 16528 16522 16514>,
			<16784 16698 16559 16529 16520 16515>,
			<16787 16705 16571 16530 16518 16515>,
			<16784 16709 16584 16526 16500 16497>,
			<16778 16714 16597 16519 16480 16472>,
			<16777 16717 16604 16515 16477 16468>,
			<16783 16721 16610 16513 16477 16469>,
			<16792 16722 16612 16513 16478 16470>,
			<16804 16716 16608 16517 16481 16472>,
			<16821 16705 16605 16522 16483 16474>,
			<16840 16692 16607 16519 16478 16466>,
			<16859 16689 16615 16513 16467 16453>,
			<16817 16678 16608 16503 16466 16455>,
			<16817 16689 16627 16510 16479 16471>,
			<16831 16707 16653 16527 16492 16491>,
			<16848 16731 16686 16547 16516 16517>,
			<16859 16766 16728 16568 16523 16524>,
			<16847 16772 16744 16538 16482 16472>,
			<16821 16734 16719 16529 16472 16462>,
			<16822 16730 16725 16545 16478 16467>,
			<16944 16743 16761 16571 16504 16486>,
			<16944 16743 16761 16571 16504 16486>,
			<16944 16743 16761 16571 16504 16486>;
	};

	qcom,pc-temp-y5-lut {
		qcom,lut-col-legend = <(-10) 0 10 25 40 50>;
		qcom,lut-row-legend = <10000 9800 9600 9400 9200 9000>,
			<8800 8600 8400 8200 8000 7800>,
			<7600 7400 7200 7000 6800 6600>,
			<6400 6200 6000 5800 5600 5400>,
			<5200 5000 4800 4600 4400 4200>,
			<4000 3800 3600 3400 3200 3000>,
			<2800 2600 2400 2200 2000 1800>,
			<1600 1400 1200 1000 900 800>,
			<700 600 500 400 300 200>,
			<100 0>;
		qcom,lut-data = <13870 11476 14714 17867 16453 17361>,
			<12848 11929 15015 17571 16810 17711>,
			<12387 12444 15313 17154 17011 17948>,
			<12380 12956 15572 16676 17094 18092>,
			<12717 13401 15756 16199 17098 18163>,
			<13295 13714 15831 15783 17060 18183>,
			<15497 13902 15780 15300 16914 18110>,
			<18417 14066 15694 14854 16647 17944>,
			<18360 14340 15685 14875 16302 17719>,
			<14838 14952 15710 15397 15781 17314>,
			<12461 15319 15723 15738 15512 16861>,
			<14463 14797 15248 15417 15948 16368>,
			<17779 13958 14542 14816 16583 15882>,
			<18398 14643 14581 14404 16500 15600>,
			<17197 19401 15571 14061 15591 15512>,
			<16263 22607 17005 13901 14945 15522>,
			<15269 20532 19942 14103 14787 15254>,
			<13733 17162 23101 14645 14698 14856>,
			<13465 16516 23250 16051 14732 14862>,
			<13944 16884 21563 20208 15009 15010>,
			<14330 17438 20280 22809 15489 15263>,
			<14297 18496 19857 22760 17814 16556>,
			<14091 19827 19529 22608 20649 18330>,
			<13762 20579 19195 22170 20834 18967>,
			<12880 21280 18756 20688 19676 19287>,
			<12280 21280 18552 19423 18463 19401>,
			<12281 18478 19626 18789 17286 18531>,
			<12294 14334 21118 18310 16334 17245>,
			<12340 13079 21217 18266 16219 16811>,
			<12553 12777 20576 18500 16392 16610>,
			<12793 12662 19916 18845 16636 16536>,
			<12994 12794 19083 19484 17201 16551>,
			<13166 13047 18286 20290 17950 16595>,
			<13196 13222 18201 20750 18457 16945>,
			<13161 13427 18368 21099 18851 18229>,
			<13134 13605 18613 21262 19213 18958>,
			<13222 13788 19173 20944 19635 18811>,
			<13393 14014 19752 20281 19955 18524>,
			<13393 14185 19746 19703 19654 18257>,
			<13045 14357 19373 19162 18464 17969>,
			<12727 14448 19035 18553 17745 17701>,
			<12627 14417 18760 17544 17690 17421>,
			<12591 14325 18472 16845 17433 17283>,
			<12802 13906 16418 17205 16491 17418>,
			<13056 13485 14911 17154 16903 18741>,
			<13220 13358 14205 16869 16830 18340>,
			<13290 13129 14054 17634 16300 16959>,
			<13571 13269 13917 16545 17720 17749>,
			<13744 13769 14338 16783 18289 17477>,
			<14101 14120 14300 17319 18049 17080>,
			<14065 14275 14384 17243 17178 17155>,
			<13753 13909 13973 17362 17552 18476>,
			<13217 13470 13997 20238 20440 19225>,
			<12300 13636 13777 21129 24321 23913>,
			<12300 13636 13777 21129 24321 23913>,
			<12300 13636 13777 21129 24321 23913>;
	};

	qcom,pc-temp-y6-lut {
		qcom,lut-col-legend = <(-10) 0 10 25 40 50>;
		qcom,lut-row-legend = <10000 9800 9600 9400 9200 9000>,
			<8800 8600 8400 8200 8000 7800>,
			<7600 7400 7200 7000 6800 6600>,
			<6400 6200 6000 5800 5600 5400>,
			<5200 5000 4800 4600 4400 4200>,
			<4000 3800 3600 3400 3200 3000>,
			<2800 2600 2400 2200 2000 1800>,
			<1600 1400 1200 1000 900 800>,
			<700 600 500 400 300 200>,
			<100 0>;
		qcom,lut-data = <6421 5766 5330 5093 5036 5024>,
			<6386 5768 5334 5091 5035 5024>,
			<6354 5767 5334 5090 5035 5024>,
			<6323 5764 5334 5090 5036 5024>,
			<6294 5759 5332 5090 5036 5025>,
			<6267 5753 5329 5090 5037 5025>,
			<6244 5745 5324 5090 5038 5026>,
			<6223 5735 5319 5091 5039 5027>,
			<6192 5724 5315 5093 5041 5029>,
			<6148 5712 5313 5095 5042 5030>,
			<6123 5706 5312 5098 5044 5032>,
			<6128 5710 5313 5100 5047 5033>,
			<6135 5716 5315 5103 5049 5035>,
			<6122 5715 5318 5107 5052 5037>,
			<6037 5697 5324 5112 5055 5040>,
			<5971 5674 5328 5118 5058 5042>,
			<5959 5646 5323 5122 5062 5045>,
			<5951 5618 5313 5125 5065 5048>,
			<5945 5605 5300 5129 5070 5052>,
			<5940 5600 5281 5134 5077 5058>,
			<5934 5595 5265 5137 5080 5062>,
			<5924 5590 5253 5121 5068 5053>,
			<5914 5586 5244 5094 5050 5038>,
			<5912 5580 5240 5084 5041 5030>,
			<5917 5571 5237 5080 5035 5025>,
			<5925 5566 5237 5078 5033 5023>,
			<5936 5571 5238 5079 5034 5024>,
			<5951 5581 5241 5081 5035 5025>,
			<5967 5594 5241 5083 5037 5027>,
			<5984 5613 5241 5086 5041 5030>,
			<6001 5634 5240 5090 5044 5033>,
			<6018 5654 5245 5093 5049 5037>,
			<6036 5676 5256 5096 5053 5040>,
			<6054 5699 5267 5098 5053 5042>,
			<6072 5723 5281 5101 5053 5042>,
			<6091 5750 5296 5102 5053 5042>,
			<6112 5778 5313 5101 5048 5037>,
			<6135 5808 5331 5101 5042 5029>,
			<6159 5840 5348 5101 5041 5027>,
			<6182 5875 5366 5102 5041 5028>,
			<6208 5910 5384 5103 5042 5029>,
			<6239 5943 5404 5106 5044 5031>,
			<6276 5977 5426 5110 5045 5032>,
			<6320 6014 5450 5113 5042 5028>,
			<6368 6059 5482 5115 5040 5027>,
			<6337 6054 5477 5112 5043 5031>,
			<6361 6084 5505 5119 5048 5036>,
			<6408 6133 5539 5126 5057 5046>,
			<6460 6188 5581 5139 5067 5055>,
			<6524 6245 5617 5150 5069 5057>,
			<6593 6294 5650 5139 5052 5038>,
			<6695 6350 5684 5142 5049 5036>,
			<6863 6464 5791 5165 5057 5040>,
			<7418 6622 5941 5188 5071 5052>,
			<7418 6622 5941 5188 5071 5052>,
			<7418 6622 5941 5188 5071 5052>;
	};

};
